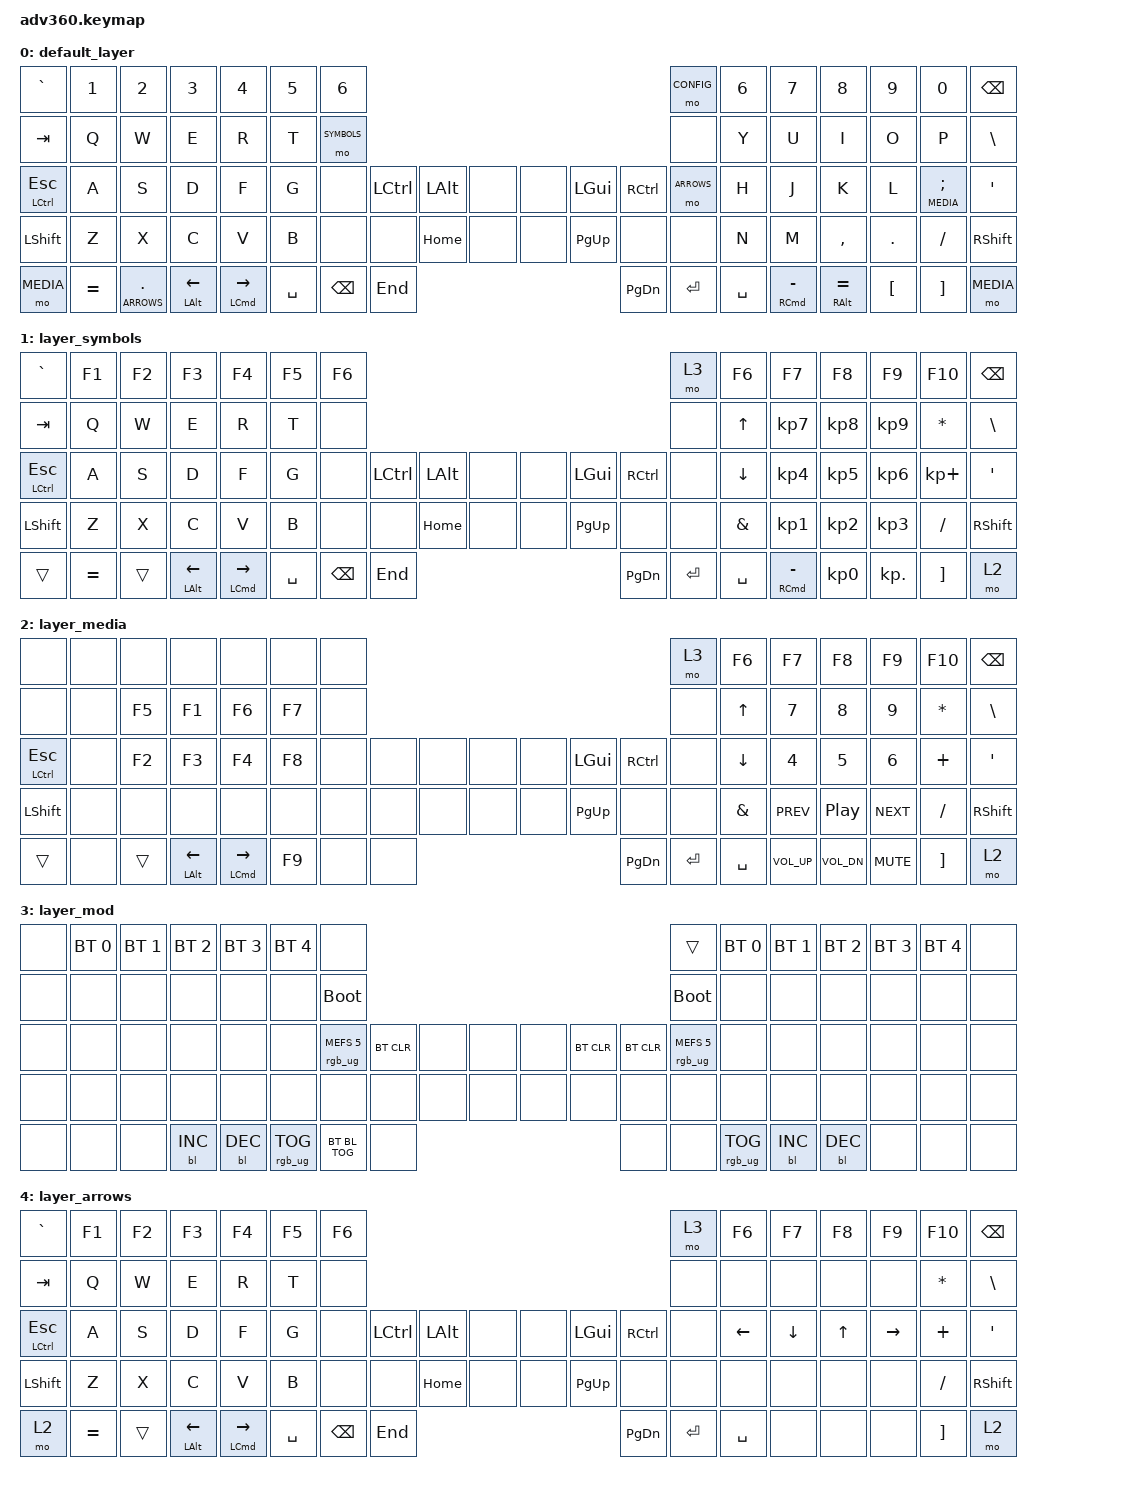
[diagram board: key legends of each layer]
/*
 * Copyright (c) 2020 The ZMK Contributors
 *
 * SPDX-License-Identifier: MIT
 */


/* THIS FILE WAS GENERATED!
 *
 * This file was generated automatically. You may or may not want to
 * edit it directly.
 */

#include <behaviors.dtsi>
#include <dt-bindings/zmk/keys.h>
#include <dt-bindings/zmk/bt.h>
#include <dt-bindings/zmk/rgb.h>
#include <dt-bindings/zmk/backlight.h>


#define DEFAULT 0
#define SYMBOLS 1
#define MEDIA 2
#define CONFIG 3
#define ARROWS 4

/ {
  behaviors {
    #include "macros.dtsi"

    hm: homerow_mods {
        compatible = "zmk,behavior-hold-tap";
        label = "HOMEROW_MODS";
        #binding-cells = <2>;
        tapping-term-ms = <200>;
        quick_tap_ms = <175>;
        flavor = "tap-preferred";
        bindings = <&kp>, <&kp>;
    };
  };

  keymap {
    compatible = "zmk,keymap";

    default_layer {
      bindings = <
          &kp GRAVE       &kp N1        &kp N2        &kp N3        &kp N4        &kp N5                      &kp N6                                                                                                                      &mo CONFIG                    &kp N6        &kp N7        &kp N8        &kp N9        &kp N0       &kp BSPC   
           &kp TAB        &kp Q         &kp W         &kp E         &kp R         &kp T                    &mo SYMBOLS                                                                                                                      &none                       &kp Y         &kp U         &kp I         &kp O         &kp P        &kp BSLH   
        &mt LCTRL ESC     &kp A         &kp S         &kp D         &kp F         &kp G                       &none                     &kp LCTRL      &kp LALT       &none         &none        &kp LGUI     &kp RCTRL                   &mo ARROWS                    &kp H         &kp J         &kp K         &kp L     &lt MEDIA SEMI   &kp SQT    
          &kp LSHFT       &kp Z         &kp X         &kp C         &kp V         &kp B                       &none                       &none        &kp HOME       &none         &none       &kp PG_UP       &none                       &none                       &kp N         &kp M       &kp COMMA      &kp DOT       &kp FSLH     &kp RSHFT   
          &mo MEDIA     &kp EQUAL   &lt ARROWS DOT&mt LALT LEFT &mt LCMD RIGHT                              &kp SPACE                    &kp BSPC      &kp END                                  &kp PG_DN     &kp ENTER                   &kp SPACE                               &mt RCMD MINUS&mt RALT EQUAL   &kp LBKT      &kp RBKT     &mo MEDIA   
        
        >;
      };

    layer_symbols {
      bindings = <
          &kp GRAVE       &kp F1        &kp F2        &kp F3        &kp F4        &kp F5                      &kp F6                                                                                                                        &mo 3                       &kp F6        &kp F7        &kp F8        &kp F9       &kp F10       &kp BSPC   
           &kp TAB        &kp Q         &kp W         &kp E         &kp R         &kp T                       &none                                                                                                                         &none                       &kp UP      &kp KP_N7     &kp KP_N8     &kp KP_N9      &kp STAR      &kp BSLH   
        &mt LCTRL ESC     &kp A         &kp S         &kp D         &kp F         &kp G                       &none                     &kp LCTRL      &kp LALT       &none         &none        &kp LGUI     &kp RCTRL                     &none                      &kp DOWN     &kp KP_N4     &kp KP_N5     &kp KP_N6    &kp KP_PLUS     &kp SQT    
          &kp LSHFT       &kp Z         &kp X         &kp C         &kp V         &kp B                       &none                       &none        &kp HOME       &none         &none       &kp PG_UP       &none                       &none                      &kp AMPS     &kp KP_N1     &kp KP_N2     &kp KP_N3      &kp FSLH     &kp RSHFT   
            &trans      &kp EQUAL       &trans    &mt LALT LEFT &mt LCMD RIGHT                              &kp SPACE                    &kp BSPC      &kp END                                  &kp PG_DN     &kp ENTER                   &kp SPACE                               &mt RCMD MINUS  &kp KP_N0     &kp KP_DOT     &kp RBKT       &mo 2     
        
        >;
      };

    layer_media {
      bindings = <
            &none         &none         &none         &none         &none         &none                       &none                                                                                                                                       &mo 3                       &kp F6        &kp F7        &kp F8        &kp F9       &kp F10       &kp BSPC   
            &none         &none         &kp F5        &kp F1        &kp F6        &kp F7                      &none                                                                                                                                       &none                       &kp UP        &kp 7         &kp 8         &kp 9        &kp STAR      &kp BSLH   
        &mt LCTRL ESC     &none         &kp F2        &kp F3        &kp F4        &kp F8                      &none                                     &none         &none         &none         &none        &kp LGUI     &kp RCTRL                     &none                      &kp DOWN       &kp 4         &kp 5         &kp 6        &kp PLUS      &kp SQT    
          &kp LSHFT       &none         &none         &none         &none         &none                       &none                                     &none         &none         &none         &none       &kp PG_UP       &none                       &none                      &kp AMPS     &kp C_PREV     &kp C_PP     &kp C_NEXT     &kp FSLH     &kp RSHFT   
            &trans        &none         &trans    &mt LALT LEFT &mt LCMD RIGHT                                &kp F9                                    &none         &none                                   &kp PG_DN     &kp ENTER                   &kp SPACE                                &kp C_VOL_UP  &kp C_VOL_DN   &kp C_MUTE     &kp RBKT       &mo 2     
        
        >;
      };

    layer_mod {
      bindings = <
                &none              &bt BT_SEL 0          &bt BT_SEL 1          &bt BT_SEL 2          &bt BT_SEL 3          &bt BT_SEL 4                                   &none                                                                                                                                                                                                 &trans                                   &bt BT_SEL 0          &bt BT_SEL 1          &bt BT_SEL 2          &bt BT_SEL 3          &bt BT_SEL 4             &none         
                &none                 &none                 &none                 &none                 &none                 &none                                    &bootloader                                                                                                                                                                                           &bootloader                                    &none                 &none                 &none                 &none                 &none                 &none         
                &none                 &none                 &none                 &none                 &none                 &none                               &rgb_ug RGB_MEFS_CMD 5                            &bt BT_CLR              &none                 &none                 &none               &bt BT_CLR            &bt BT_CLR                            &rgb_ug RGB_MEFS_CMD 5                              &none                 &none                 &none                 &none                 &none                 &none         
                &none                 &none                 &none                 &none                 &none                 &none                                       &none                                       &none                 &none                 &none                 &none                 &none                 &none                                       &none                                       &none                 &none                 &none                 &none                 &none                 &none         
                &none                 &none                 &none               &bl BL_INC            &bl BL_DEC                                                     &rgb_ug RGB_TOG                                &bt BL_TOG              &none                                                             &none                 &none                                  &rgb_ug RGB_TOG                                                      &bl BL_INC            &bl BL_DEC              &none                 &none                 &none         
        
        >;
      };

    layer_arrows {
      bindings = <
          &kp GRAVE       &kp F1        &kp F2        &kp F3        &kp F4        &kp F5                      &kp F6                                                                                                                        &mo 3                       &kp F6        &kp F7        &kp F8        &kp F9       &kp F10       &kp BSPC   
           &kp TAB        &kp Q         &kp W         &kp E         &kp R         &kp T                       &none                                                                                                                         &none                       &none         &none         &none         &none        &kp STAR      &kp BSLH   
        &mt LCTRL ESC     &kp A         &kp S         &kp D         &kp F         &kp G                       &none                     &kp LCTRL      &kp LALT       &none         &none        &kp LGUI     &kp RCTRL                     &none                      &kp LEFT      &kp DOWN       &kp UP      &kp RIGHT      &kp PLUS      &kp SQT    
          &kp LSHFT       &kp Z         &kp X         &kp C         &kp V         &kp B                       &none                       &none        &kp HOME       &none         &none       &kp PG_UP       &none                       &none                       &none         &none         &none         &none        &kp FSLH     &kp RSHFT   
            &mo 2       &kp EQUAL       &trans    &mt LALT LEFT &mt LCMD RIGHT                              &kp SPACE                    &kp BSPC      &kp END                                  &kp PG_DN     &kp ENTER                   &kp SPACE                                   &none         &none         &none        &kp RBKT       &mo 2     
        
        >;
      };

  };
};
